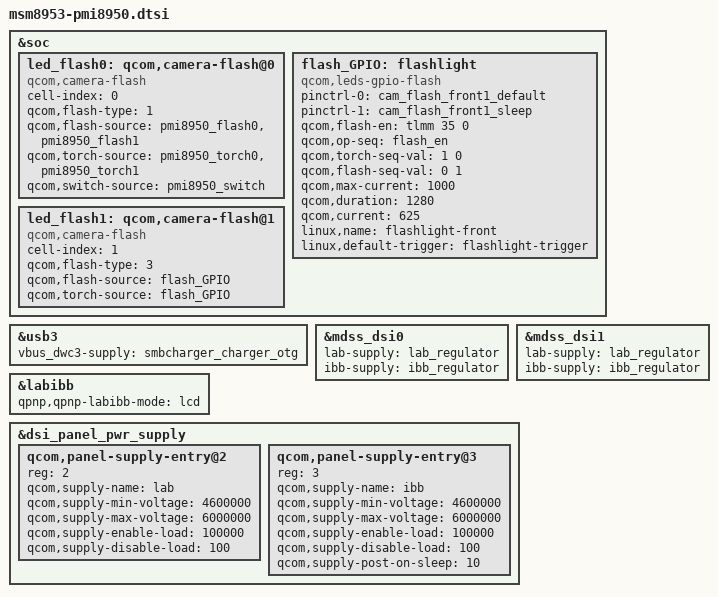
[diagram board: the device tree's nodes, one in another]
/*
 * Copyright (c) 2017, The Linux Foundation. All rights reserved.
 *
 * This program is free software; you can redistribute it and/or modify
 * it under the terms of the GNU General Public License version 2 and
 * only version 2 as published by the Free Software Foundation.
 *
 * This program is distributed in the hope that it will be useful,
 * but WITHOUT ANY WARRANTY; without even the implied warranty of
 * MERCHANTABILITY or FITNESS FOR A PARTICULAR PURPOSE.  See the
 * GNU General Public License for more details.
 */

&soc {
	led_flash0: qcom,camera-flash@0 {
		cell-index = <0>;
		compatible = "qcom,camera-flash";
		qcom,flash-type = <1>;
		qcom,flash-source = <&pmi8950_flash0 &pmi8950_flash1>;
		qcom,torch-source = <&pmi8950_torch0 &pmi8950_torch1>;
		qcom,switch-source = <&pmi8950_switch>;
	};

	flash_GPIO:flashlight {
		compatible = "qcom,leds-gpio-flash";
		status = "okay";
		pinctrl-names = "flash_default", "flash_sleep";
		pinctrl-0 = <&cam_flash_front1_default>;
		pinctrl-1 = <&cam_flash_front1_sleep>;
		qcom,flash-en = <&tlmm 35 0>;
		qcom,op-seq = "flash_en";
		qcom,torch-seq-val = <1 0>;
		qcom,flash-seq-val = <0 1>;
		qcom,max-current = <1000>;
		qcom,duration = <1280>;
		qcom,current = <625>;
		linux,name = "flashlight-front";
		linux,default-trigger = "flashlight-trigger";
	};

	led_flash1: qcom,camera-flash@1 {
		cell-index = <1>;
		compatible = "qcom,camera-flash";
		qcom,flash-type = <3>;
		qcom,flash-source = <&flash_GPIO>;
		qcom,torch-source = <&flash_GPIO>;
	};


};

&usb3 {
	vbus_dwc3-supply = <&smbcharger_charger_otg>;
};

&mdss_dsi0 {
	lab-supply = <&lab_regulator>;
	ibb-supply = <&ibb_regulator>;
};

&mdss_dsi1 {
	lab-supply = <&lab_regulator>;
	ibb-supply = <&ibb_regulator>;
};

&labibb {
	status = "ok";
	qpnp,qpnp-labibb-mode = "lcd";
};

&dsi_panel_pwr_supply {
	qcom,panel-supply-entry@2 {
		reg = <2>;
		qcom,supply-name = "lab";
		qcom,supply-min-voltage = <4600000>;
		qcom,supply-max-voltage = <6000000>;
		qcom,supply-enable-load = <100000>;
		qcom,supply-disable-load = <100>;
	};

	qcom,panel-supply-entry@3 {
		reg = <3>;
		qcom,supply-name = "ibb";
		qcom,supply-min-voltage = <4600000>;
		qcom,supply-max-voltage = <6000000>;
		qcom,supply-enable-load = <100000>;
		qcom,supply-disable-load = <100>;
		qcom,supply-post-on-sleep = <10>;
	};
};
